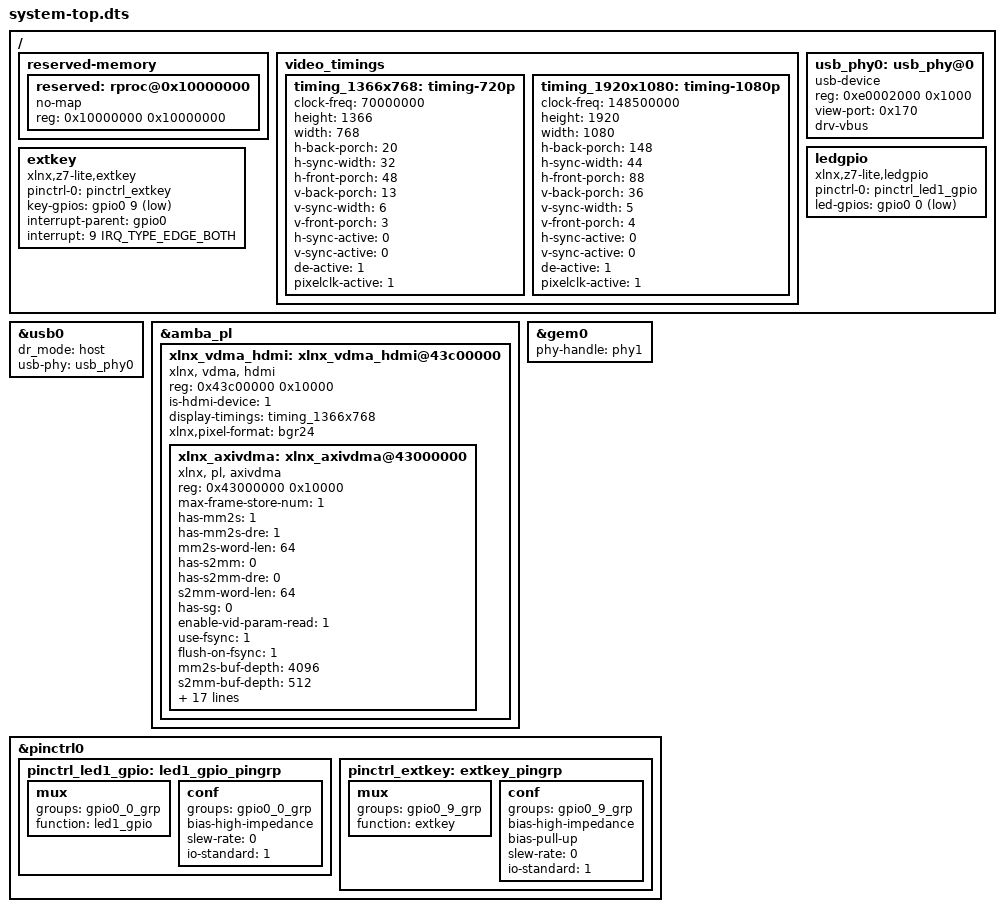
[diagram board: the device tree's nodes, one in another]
/*
 * CAUTION: This file is automatically generated by Xilinx.
 * Version:  
 * Today is: Tue Nov  8 15:11:55 2022
 */


/dts-v1/;
#include "../dt-bindings/gpio.h"
#include "../dt-bindings/irq.h"
#include "zynq-7000.dtsi"
#include "pl.dtsi"
#include "pcw.dtsi"
#include "system-conf.dtsi"

/ {	
    reserved-memory {
        #address-cells = <1>;
        #size-cells = <1>;
        ranges;
    
        reserved: rproc@0x10000000 {
            no-map;
            reg = <0x10000000 0x10000000>;
        };
    };
    
    video_timings {
        timing_1366x768: timing-720p {
            clock-freq = <70000000>;
            height = <1366>;
            width = <768>;
            
            h-back-porch = <20>;
            h-sync-width = <32>;
            h-front-porch = <48>;
            v-back-porch = <13>;
            v-sync-width = <6>;
            v-front-porch = <3>;
            
            h-sync-active = <0>;
            v-sync-active = <0>;
            de-active = <1>;
            pixelclk-active = <1>;
        };

        timing_1920x1080: timing-1080p {
            clock-freq = <148500000>;
            height = <1920>;
            width = <1080>;
            
            h-back-porch = <148>;
            h-sync-width = <44>;
            h-front-porch = <88>;
            v-back-porch = <36>;
            v-sync-width = <5>;
            v-front-porch = <4>;
            
            h-sync-active = <0>;
            v-sync-active = <0>;
            de-active = <1>;
            pixelclk-active = <1>;
        };
    };
    
    usb_phy0: usb_phy@0 {
        compatible = "usb-device";
        #phy-cells = <0>;
        reg = <0xe0002000 0x1000>;
        view-port = <0x170>;
        drv-vbus;
    };

    ledgpio {
        compatible = "xlnx,z7-lite,ledgpio";
        pinctrl-0 = <&pinctrl_led1_gpio>;
        led-gpios = <&gpio0 0 GPIO_ACTIVE_LOW>;
        
        status = "okay";
    };
    
    extkey {
        compatible = "xlnx,z7-lite,extkey";
        pinctrl-0 = <&pinctrl_extkey>;
        key-gpios = <&gpio0 9 GPIO_ACTIVE_LOW>;
        interrupt-parent = <&gpio0>;
        interrupt = <9 IRQ_TYPE_EDGE_BOTH>;
        
        status = "okay";
    };
};

&usb0 {
    dr_mode = "host";
    usb-phy = <&usb_phy0>;
};

&amba_pl {
    xlnx_vdma_hdmi: xlnx_vdma_hdmi@43c00000 {
        compatible = "xlnx, vdma, hdmi";
        reg = <0x43c00000 0x10000>;
        status = "okay";
        
        is-hdmi-device = <1>;
//      display-timings = <&timing_1920x1080>;
        display-timings = <&timing_1366x768>;
        xlnx,pixel-format = "bgr24";

        #address-cells = <1>;
        #size-cells = <1>;

        xlnx_axivdma: xlnx_axivdma@43000000 {
            compatible = "xlnx, pl, axivdma";
            reg = <0x43000000 0x10000>;

            max-frame-store-num = <1>;
            has-mm2s = <1>;
            has-mm2s-dre = <1>;
            mm2s-word-len = <64>;
            has-s2mm = <0>;
            has-s2mm-dre = <0>;
            s2mm-word-len = <64>;
            has-sg = <0>;
            enable-vid-param-read = <1>;

            use-fsync = <1>;
            flush-on-fsync = <1>;
            mm2s-buf-depth = <4096>;
            s2mm-buf-depth = <512>;
            mm2s-gen-lock = <0>;
            s2mm-gen-lock = <0>;
            internal-gen-lock = <1>;
            s2mm-sof = <1>;
            mm2s-stream-width = <32>;
            s2mm-stream-width = <32>;
            mm2s-thres-reg-en = <0>;
            mm2s-frm-store-reg-en = <0>;
            mm2s-dly-cntr-en = <1>;
            mm2s-frm-cntr-en = <1>;
            s2mm-thres-reg-en = <0>;
            s2mm-frm-store-reg-en = <0>;
            s2mm-sly-cntr-en = <1>;
            s2mm-frm-cntr-en = <1>;
            enable-all-dbg-features = <0>;
            addr-width = <32>;
            has-Vertical-filp = <0>;
        };
    };
};

&gem0 {
    phy-handle = <&phy1>;
    status = "okay";
};

&pinctrl0 {
    pinctrl_led1_gpio: led1_gpio_pingrp {
        mux {
            groups = "gpio0_0_grp";
            function = "led1_gpio";
        };

        conf {
            groups = "gpio0_0_grp";
            bias-high-impedance;
            slew-rate = <0>;
            io-standard = <1>;
        };
    };

    pinctrl_extkey: extkey_pingrp {
        mux {
            groups = "gpio0_9_grp";
            function = "extkey";
        };

        conf {
            groups = "gpio0_9_grp";
            bias-high-impedance;
            bias-pull-up;
            slew-rate = <0>;
            io-standard = <1>;
        };
    };
};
